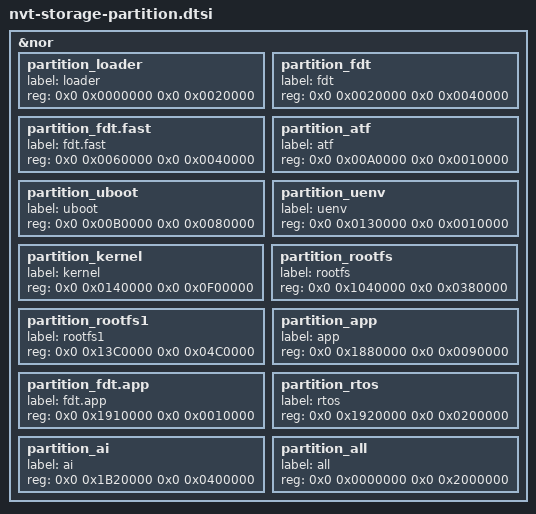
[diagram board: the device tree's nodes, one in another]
/*
 * Novatek Ltd. BSP part of dts
 */

&nor {
	partition_loader {      label = "loader";       reg = <0x0 0x0000000 0x0 0x0020000>; }; /* Fixed */
	partition_fdt {         label = "fdt";          reg = <0x0 0x0020000 0x0 0x0040000>; }; /* Fixed */
	partition_fdt.fast {    label = "fdt.fast";     reg = <0x0 0x0060000 0x0 0x0040000>; }; /* Fixed */
	partition_atf {         label = "atf";          reg = <0x0 0x00A0000 0x0 0x0010000>; };
	partition_uboot {       label = "uboot";        reg = <0x0 0x00B0000 0x0 0x0080000>; };
	partition_uenv {        label = "uenv";         reg = <0x0 0x0130000 0x0 0x0010000>; };
	partition_kernel {      label = "kernel";       reg = <0x0 0x0140000 0x0 0x0F00000>; };
	partition_rootfs {      label = "rootfs";       reg = <0x0 0x1040000 0x0 0x0380000>; };
	partition_rootfs1 {     label = "rootfs1";      reg = <0x0 0x13C0000 0x0 0x04C0000>; };
	partition_app {         label = "app";          reg = <0x0 0x1880000 0x0 0x0090000>; };
	partition_fdt.app {     label = "fdt.app";      reg = <0x0 0x1910000 0x0 0x0010000>; };
	partition_rtos {        label = "rtos";         reg = <0x0 0x1920000 0x0 0x0200000>; };
	partition_ai {          label = "ai";           reg = <0x0 0x1B20000 0x0 0x0400000>; };
	partition_all {         label = "all";          reg = <0x0 0x0000000 0x0 0x2000000>; };
};
